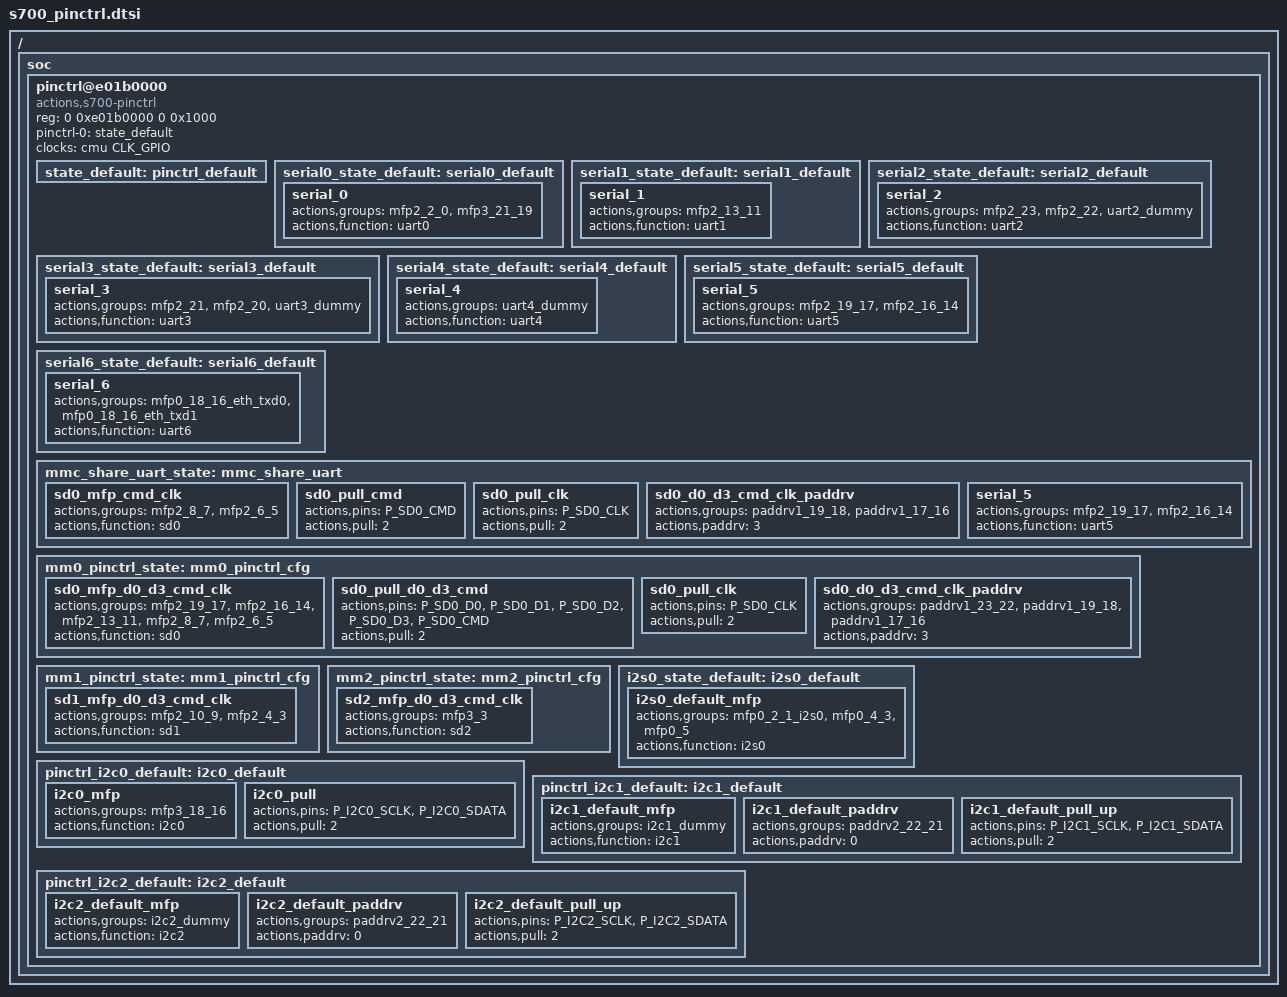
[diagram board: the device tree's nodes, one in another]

/ {
	soc {
	
	pinctrl@e01b0000 {
			compatible = "actions,s700-pinctrl";
			reg = <0 0xe01b0000 0 0x1000>;
			
			pinctrl-names = "default";
			pinctrl-0 = <&state_default>;
	
			clocks = <&cmu CLK_GPIO>;
			clock-names = "mfp";
	
			state_default: pinctrl_default {
			};
			
		serial0_state_default: serial0_default{
			serial_0{
				actions,groups = "mfp2_2_0","mfp3_21_19";
				actions,function = "uart0";
			};
		};

		serial1_state_default: serial1_default{
			serial_1{
				actions,groups = "mfp2_13_11";
				actions,function = "uart1";
			};
		};

		serial2_state_default: serial2_default{
			serial_2{
				actions,groups = "mfp2_23","mfp2_22","uart2_dummy";
				actions,function = "uart2";
			};
		};

		serial3_state_default: serial3_default{
			serial_3{
				actions,groups = "mfp2_21","mfp2_20","uart3_dummy";
				actions,function = "uart3";
			};
		};

		serial4_state_default: serial4_default{
			serial_4{
				actions,groups = "uart4_dummy";
				actions,function = "uart4";
			};
		};

		serial5_state_default: serial5_default{
			serial_5{
				actions,groups = "mfp2_19_17","mfp2_16_14";
				actions,function = "uart5";
			};
		};

		serial6_state_default: serial6_default{
			serial_6{
				actions,groups = "mfp0_18_16_eth_txd0", "mfp0_18_16_eth_txd1";
				actions,function = "uart6";
			};
		};
		
		mmc_share_uart_state: mmc_share_uart {
			sd0_mfp_cmd_clk {
				actions,groups = "mfp2_8_7", "mfp2_6_5";
				actions,function = "sd0";
			};

			sd0_pull_cmd {
				actions,pins = "P_SD0_CMD";
				actions,pull = <2>;
			};

			sd0_pull_clk {
				actions,pins = "P_SD0_CLK";
				actions,pull = <2>;
			};

			sd0_d0_d3_cmd_clk_paddrv  {
				actions,groups  = "paddrv1_19_18","paddrv1_17_16";
				actions,paddrv  = <3>;
			};

			serial_5 {
				actions,groups = "mfp2_19_17","mfp2_16_14";
				actions,function = "uart5";
			};
		};

		mm0_pinctrl_state: mm0_pinctrl_cfg {
			sd0_mfp_d0_d3_cmd_clk {
				actions,groups = "mfp2_19_17", "mfp2_16_14", "mfp2_13_11", "mfp2_8_7", "mfp2_6_5";
				actions,function = "sd0";
			};

			sd0_pull_d0_d3_cmd {
				actions,pins = "P_SD0_D0", "P_SD0_D1", "P_SD0_D2", "P_SD0_D3", "P_SD0_CMD";
				actions,pull = <2>;
			};

			sd0_pull_clk {
				actions,pins = "P_SD0_CLK";
				actions,pull = <2>;
			};

			sd0_d0_d3_cmd_clk_paddrv  {
				actions,groups  = "paddrv1_23_22","paddrv1_19_18","paddrv1_17_16";
				actions,paddrv  = <3>; /*level 3,0~3*/
			};
		};
		
		mm1_pinctrl_state: mm1_pinctrl_cfg {
			sd1_mfp_d0_d3_cmd_clk {
				actions,groups = "mfp2_10_9", "mfp2_4_3";
				actions,function = "sd1";
			};
		};
		
		mm2_pinctrl_state: mm2_pinctrl_cfg {
			sd2_mfp_d0_d3_cmd_clk {
				actions,groups = "mfp3_3";
				actions,function = "sd2";
			};
		};
		
		i2s0_state_default: i2s0_default {
			i2s0_default_mfp {
				actions,groups = "mfp0_2_1_i2s0", "mfp0_4_3", "mfp0_5";
				actions,function = "i2s0";
			};
		};
		
		pinctrl_i2c0_default: i2c0_default {
			i2c0_mfp {
				actions,groups = "mfp3_18_16";
				actions,function = "i2c0";
			};

			i2c0_pull {
				actions,pins = "P_I2C0_SCLK", "P_I2C0_SDATA";
				actions,pull = <2>;
			};
		};
		
		pinctrl_i2c1_default: i2c1_default {
			i2c1_default_mfp {
				actions,groups = "i2c1_dummy";
				actions,function = "i2c1";
			};

			i2c1_default_paddrv {
				actions,groups = "paddrv2_22_21";
				actions,paddrv = <0>;/*level 1*/
			};

			i2c1_default_pull_up {
				actions,pins = "P_I2C1_SCLK","P_I2C1_SDATA";
				actions,pull = <2>; /*pull up*/
			};
		};
		
		pinctrl_i2c2_default: i2c2_default {
			i2c2_default_mfp {
				actions,groups = "i2c2_dummy";
				actions,function = "i2c2";
			};

			i2c2_default_paddrv {
				actions,groups = "paddrv2_22_21";
				actions,paddrv = <0>;/*level 1*/
			};

			i2c2_default_pull_up {
				actions,pins = "P_I2C2_SCLK","P_I2C2_SDATA";
				actions,pull = <2>; /*pull up*/
			};
		};
	};
	};
};

